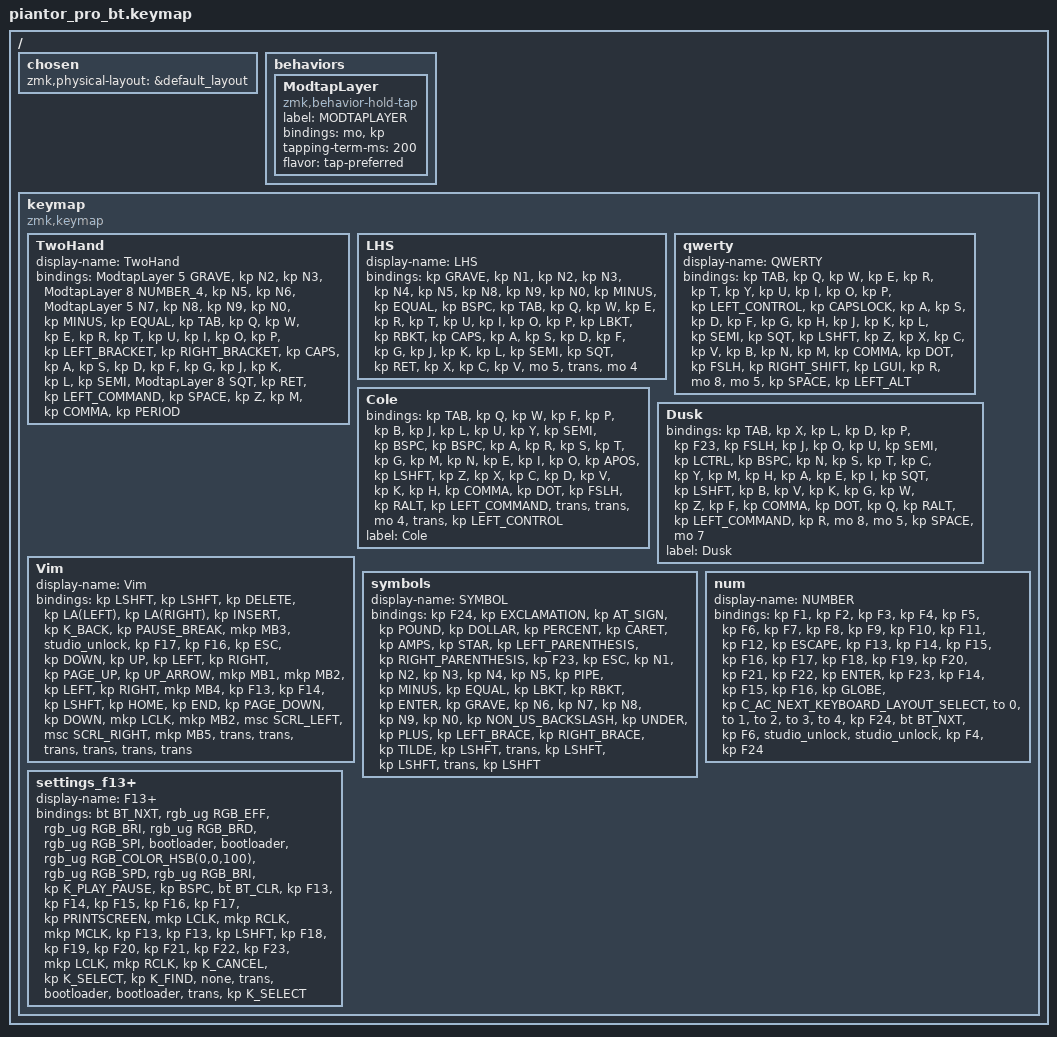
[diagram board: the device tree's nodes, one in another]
/*
 * Copyright (c) 2020 The ZMK Contributors
 *
 * SPDX-License-Identifier: MIT
 */

#include <behaviors.dtsi>
#include <dt-bindings/zmk/bt.h>
#include <dt-bindings/zmk/keys.h>
#include <dt-bindings/zmk/pointing.h>
#include <dt-bindings/zmk/rgb.h>

/ {
    chosen { zmk,physical-layout = &default_layout; };
};

/ {
    behaviors {
        ModtapLayer: ModtapLayer {
            compatible = "zmk,behavior-hold-tap";
            label = "MODTAPLAYER";
            bindings = <&mo>, <&kp>;

            #binding-cells = <2>;
            tapping-term-ms = <200>;
            flavor = "tap-preferred";
        };
    };

    keymap {
        compatible = "zmk,keymap";

        TwoHand {
            display-name = "TwoHand";
            bindings = <
&ModtapLayer 5 GRAVE  &kp N2  &kp N3  &ModtapLayer 8 NUMBER_4  &kp N5  &kp N6  &ModtapLayer 5 N7  &kp N8  &kp N9  &kp N0  &kp MINUS  &kp EQUAL  &kp TAB  &kp Q  &kp W  &kp E  &kp R  &kp T  &kp U  &kp I  &kp O  &kp P  &kp LEFT_BRACKET  &kp RIGHT_BRACKET  &kp CAPS  &kp A  &kp S  &kp D  &kp F  &kp G  &kp J  &kp K  &kp L  &kp SEMI  &ModtapLayer 8 SQT  &kp RET  &kp LEFT_COMMAND  &kp SPACE  &kp Z  &kp M  &kp COMMA  &kp PERIOD
            >;
        };

        LHS {
            display-name = "LHS";
            bindings = <
&kp GRAVE  &kp N1  &kp N2  &kp N3  &kp N4  &kp N5  &kp N8  &kp N9  &kp N0  &kp MINUS  &kp EQUAL  &kp BSPC  &kp TAB  &kp Q  &kp W  &kp E  &kp R  &kp T  &kp U  &kp I  &kp O  &kp P  &kp LBKT  &kp RBKT  &kp CAPS  &kp A  &kp S  &kp D  &kp F  &kp G  &kp J  &kp K  &kp L  &kp SEMI  &kp SQT  &kp RET  &kp X  &kp C  &kp V  &mo 5  &trans  &mo 4
            >;
        };

        qwerty {
            display-name = "QWERTY";

            // --------------------------------------------------------------------------------
            // |  TAB |  Q  |  W  |  E  |  R  |  T  |  Y  |  U   |  I  |  O  |  P  | BSPC |
            // | CTRL |  A  |  S  |  D  |  F  |  G  |  H  |  J   |  K  |  L  |  ;  |  '   |
            // | SHFT |  Z  |  X  |  C  |  V  |  B  |  N  |  M   |  ,  |  .  |  /  | ESC  |
            //                    | GUI | LWR | SPC | ENT | RSE  | ALT |

            bindings = <
&kp TAB  &kp Q  &kp W  &kp E  &kp R  &kp T  &kp Y  &kp U  &kp I  &kp O  &kp P  &kp LEFT_CONTROL  &kp CAPSLOCK  &kp A  &kp S  &kp D  &kp F  &kp G  &kp H  &kp J  &kp K  &kp L  &kp SEMI  &kp SQT  &kp LSHFT  &kp Z  &kp X  &kp C  &kp V  &kp B  &kp N  &kp M  &kp COMMA  &kp DOT  &kp FSLH  &kp RIGHT_SHIFT  &kp LGUI  &kp R  &mo 8  &mo 5  &kp SPACE  &kp LEFT_ALT
            >;
        };

        Cole {
            bindings = <
&kp TAB  &kp Q  &kp W  &kp F  &kp P  &kp B  &kp J  &kp L  &kp U  &kp Y  &kp SEMI  &kp BSPC  &kp BSPC  &kp A  &kp R  &kp S  &kp T  &kp G  &kp M  &kp N  &kp E  &kp I  &kp O  &kp APOS  &kp LSHFT  &kp Z  &kp X  &kp C  &kp D  &kp V  &kp K  &kp H  &kp COMMA  &kp DOT  &kp FSLH  &kp RALT  &kp LEFT_COMMAND  &trans  &trans  &mo 4  &trans  &kp LEFT_CONTROL
            >;

            label = "Cole";
        };

        Dusk {
            bindings = <
&kp TAB  &kp X  &kp L  &kp D  &kp P  &kp F23  &kp FSLH  &kp J  &kp O  &kp U  &kp SEMI  &kp LCTRL  &kp BSPC  &kp N  &kp S  &kp T  &kp C  &kp Y  &kp M  &kp H  &kp A  &kp E  &kp I  &kp SQT  &kp LSHFT  &kp B  &kp V  &kp K  &kp G  &kp W  &kp Z  &kp F  &kp COMMA  &kp DOT  &kp Q  &kp RALT  &kp LEFT_COMMAND  &kp R  &mo 8  &mo 5  &kp SPACE  &mo 7
            >;

            label = "Dusk";
        };

        Vim {
            display-name = "Vim";
            bindings = <
&kp LSHFT  &kp LSHFT  &kp DELETE  &kp LA(LEFT)  &kp LA(RIGHT)  &kp INSERT  &kp K_BACK  &kp PAUSE_BREAK  &mkp MB3  &studio_unlock  &kp F17  &kp F16  &kp ESC  &kp DOWN  &kp UP  &kp LEFT  &kp RIGHT  &kp PAGE_UP  &kp UP_ARROW  &mkp MB1  &mkp MB2  &kp LEFT  &kp RIGHT  &mkp MB4  &kp F13  &kp F14  &kp LSHFT  &kp HOME  &kp END  &kp PAGE_DOWN  &kp DOWN  &mkp LCLK  &mkp MB2  &msc SCRL_LEFT  &msc SCRL_RIGHT  &mkp MB5  &trans  &trans  &trans  &trans  &trans  &trans
            >;
        };

        symbols {
            display-name = "SYMBOL";

            // -----------------------------------------------------------------------------------------
            // |  TAB |  !  |  @  |  #  |  $  |  %  |  ^  |  &  |  *  |  (  |  )  | BSPC |
            // | CTRL |     |     |     |     |     |  -  |  =  |  [  |  ]  |  \  |  `   |
            // | SHFT |     |     |     |     |     |  _  |  +  |  {  |  }  | "|" |  ~   |
            //                    | GUI |     | SPC | ENT |     | ALT |

            bindings = <
&kp F24  &kp EXCLAMATION  &kp AT_SIGN  &kp POUND  &kp DOLLAR  &kp PERCENT  &kp CARET  &kp AMPS  &kp STAR  &kp LEFT_PARENTHESIS  &kp RIGHT_PARENTHESIS  &kp F23  &kp ESC  &kp N1  &kp N2  &kp N3  &kp N4  &kp N5  &kp PIPE  &kp MINUS  &kp EQUAL  &kp LBKT  &kp RBKT  &kp ENTER  &kp GRAVE  &kp N6  &kp N7  &kp N8  &kp N9  &kp N0  &kp NON_US_BACKSLASH  &kp UNDER  &kp PLUS  &kp LEFT_BRACE  &kp RIGHT_BRACE  &kp TILDE  &kp LSHFT  &trans  &kp LSHFT  &kp LSHFT  &trans  &kp LSHFT
            >;
        };

        num {
            display-name = "NUMBER";
            bindings = <
&kp F1  &kp F2  &kp F3  &kp F4  &kp F5  &kp F6  &kp F7  &kp F8  &kp F9  &kp F10  &kp F11  &kp F12  &kp ESCAPE  &kp F13  &kp F14  &kp F15  &kp F16  &kp F17  &kp F18  &kp F19  &kp F20  &kp F21  &kp F22  &kp ENTER  &kp F23  &kp F14  &kp F15  &kp F16  &kp GLOBE  &kp C_AC_NEXT_KEYBOARD_LAYOUT_SELECT  &to 0  &to 1  &to 2  &to 3  &to 4  &kp F24  &bt BT_NXT  &kp F6  &studio_unlock  &studio_unlock  &kp F4  &kp F24
            >;
        };

        settings_f13+ {
            display-name = "F13+";

            // -----------------------------------------------------------------------------------------
            // |  TAB |  1  |  2  |  3  |  4  |  5    |  6  |  7  |  8  |  9  |  0  | BSPC |
            // | CTRL | BT1 | BT2 | BT3 | BT4 | BT5   | LFT | DWN |  UP | RGT |     |      |
            // | SHFT | BTCR| RGB | RST | BOOT| Unlock|     |     |     |     |     |      |
            //                    | GUI |     | SPC   | ENT |     | ALT |

            bindings = <
&bt BT_NXT  &rgb_ug RGB_EFF  &rgb_ug RGB_BRI  &rgb_ug RGB_BRD  &rgb_ug RGB_SPI  &bootloader  &bootloader  &rgb_ug RGB_COLOR_HSB(0,0,100)  &rgb_ug RGB_SPD  &rgb_ug RGB_BRI  &kp K_PLAY_PAUSE  &kp BSPC  &bt BT_CLR  &kp F13  &kp F14  &kp F15  &kp F16  &kp F17  &kp PRINTSCREEN  &mkp LCLK  &mkp RCLK  &mkp MCLK  &kp F13  &kp F13  &kp LSHFT  &kp F18  &kp F19  &kp F20  &kp F21  &kp F22  &kp F23  &mkp LCLK  &mkp RCLK  &kp K_CANCEL  &kp K_SELECT  &kp K_FIND  &none  &trans  &bootloader  &bootloader  &trans  &kp K_SELECT
            >;
        };
    };
};
